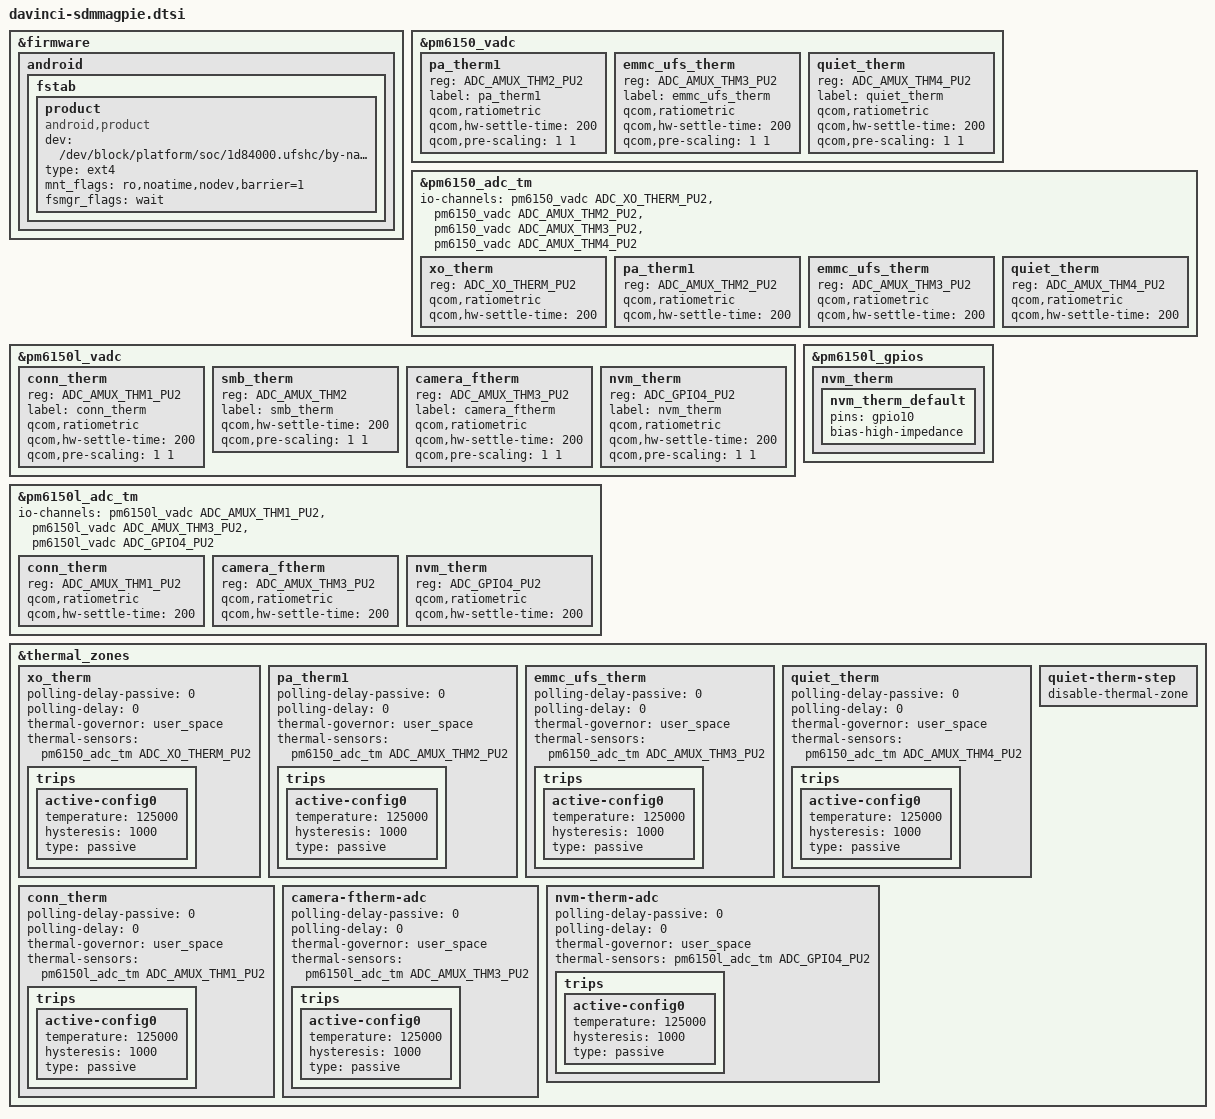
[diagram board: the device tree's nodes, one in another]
/*
 *
 * Copyright (C) 2020 The LineageOS Project
 *
 * this file is for attribution only of davinci
 * And public attribution of Xiaomi platforms (like F10 and so)
 */

#include "../common/xiaomi-sdmmagpie-common.dtsi"

#include "davinci-sdmmagpie-battery.dtsi"
#include "davinci-sdmmagpie-camera-sensor.dtsi"
#include "davinci-sdmmagpie-display.dtsi"
#include "davinci-sdmmagpie-fingerprint.dtsi"
#include "davinci-sdmmagpie-motor.dtsi"
#include "davinci-sdmmagpie-pinctrl.dtsi"
#include "davinci-sdmmagpie-touchscreen.dtsi"

&firmware {
    android {
        fstab {
            product {
              compatible = "android,product";
              dev = "/dev/block/platform/soc/1d84000.ufshc/by-name/cust";
              type = "ext4";
              mnt_flags = "ro,noatime,nodev,barrier=1";
              fsmgr_flags = "wait";
            };
        };
    };
};


&pm6150_vadc {
    pa_therm1 {
        reg = <ADC_AMUX_THM2_PU2>;
        label = "pa_therm1";
        qcom,ratiometric;
        qcom,hw-settle-time = <200>;
        qcom,pre-scaling = <1 1>;
    };

    emmc_ufs_therm {
        reg = <ADC_AMUX_THM3_PU2>;
        label = "emmc_ufs_therm";
        qcom,ratiometric;
        qcom,hw-settle-time = <200>;
        qcom,pre-scaling = <1 1>;
    };

    quiet_therm {
        reg = <ADC_AMUX_THM4_PU2>;
        label = "quiet_therm";
        qcom,ratiometric;
        qcom,hw-settle-time = <200>;
        qcom,pre-scaling = <1 1>;
    };
};

&pm6150_adc_tm {
    io-channels = <&pm6150_vadc ADC_XO_THERM_PU2>,
            <&pm6150_vadc ADC_AMUX_THM2_PU2>,
            <&pm6150_vadc ADC_AMUX_THM3_PU2>,
            <&pm6150_vadc ADC_AMUX_THM4_PU2>;

    /* Channel nodes */
    xo_therm {
        reg = <ADC_XO_THERM_PU2>;
        qcom,ratiometric;
        qcom,hw-settle-time = <200>;
    };

    pa_therm1 {
        reg = <ADC_AMUX_THM2_PU2>;
        qcom,ratiometric;
        qcom,hw-settle-time = <200>;
    };

    emmc_ufs_therm {
        reg = <ADC_AMUX_THM3_PU2>;
        qcom,ratiometric;
        qcom,hw-settle-time = <200>;
    };

    quiet_therm {
        reg = <ADC_AMUX_THM4_PU2>;
        qcom,ratiometric;
        qcom,hw-settle-time = <200>;
    };
};

&pm6150l_vadc {

    conn_therm {
        reg = <ADC_AMUX_THM1_PU2>;
        label = "conn_therm";
        qcom,ratiometric;
        qcom,hw-settle-time = <200>;
        qcom,pre-scaling = <1 1>;
    };

    smb_therm {
        reg = <ADC_AMUX_THM2>;
        label = "smb_therm";
        qcom,hw-settle-time = <200>;
        qcom,pre-scaling = <1 1>;
    };

    camera_ftherm {
        reg = <ADC_AMUX_THM3_PU2>;
        label = "camera_ftherm";
        qcom,ratiometric;
        qcom,hw-settle-time = <200>;
        qcom,pre-scaling = <1 1>;
    };

    nvm_therm {
        reg = <ADC_GPIO4_PU2>;
        label = "nvm_therm";
        qcom,ratiometric;
        qcom,hw-settle-time = <200>;
        qcom,pre-scaling = <1 1>;
    };
};

&pm6150l_gpios {
    nvm_therm {
        nvm_therm_default: nvm_therm_default {
            pins = "gpio10";
            bias-high-impedance;
        };
    };
};

&pm6150l_adc_tm {
    io-channels = <&pm6150l_vadc ADC_AMUX_THM1_PU2>,
            <&pm6150l_vadc ADC_AMUX_THM3_PU2>,
            <&pm6150l_vadc ADC_GPIO4_PU2>;

    /* Channel nodes */
    conn_therm {
        reg = <ADC_AMUX_THM1_PU2>;
        qcom,ratiometric;
        qcom,hw-settle-time = <200>;
    };

    camera_ftherm {
        reg = <ADC_AMUX_THM3_PU2>;
        qcom,ratiometric;
        qcom,hw-settle-time = <200>;
    };

    nvm_therm {
        reg = <ADC_GPIO4_PU2>;
        qcom,ratiometric;
        qcom,hw-settle-time = <200>;
    };
};

&thermal_zones {

    xo_therm {
        polling-delay-passive = <0>;
        polling-delay = <0>;
        thermal-governor = "user_space";
        thermal-sensors = <&pm6150_adc_tm ADC_XO_THERM_PU2>;
        trips {
            active-config0 {
                temperature = <125000>;
                hysteresis = <1000>;
                type = "passive";
            };
        };
    };

    pa_therm1 {
        polling-delay-passive = <0>;
        polling-delay = <0>;
        thermal-governor = "user_space";
        thermal-sensors = <&pm6150_adc_tm ADC_AMUX_THM2_PU2>;
        trips {
            active-config0 {
                temperature = <125000>;
                hysteresis = <1000>;
                type = "passive";
            };
        };
    };

    emmc_ufs_therm {
        polling-delay-passive = <0>;
        polling-delay = <0>;
        thermal-governor = "user_space";
        thermal-sensors = <&pm6150_adc_tm ADC_AMUX_THM3_PU2>;
        trips {
            active-config0 {
                temperature = <125000>;
                hysteresis = <1000>;
                type = "passive";
            };
        };
    };

    quiet_therm {
        polling-delay-passive = <0>;
        polling-delay = <0>;
        thermal-governor = "user_space";
        thermal-sensors = <&pm6150_adc_tm ADC_AMUX_THM4_PU2>;
        trips {
            active-config0 {
                temperature = <125000>;
                hysteresis = <1000>;
                type = "passive";
            };
        };
    };

    conn_therm {
        polling-delay-passive = <0>;
        polling-delay = <0>;
        thermal-governor = "user_space";
        thermal-sensors = <&pm6150l_adc_tm ADC_AMUX_THM1_PU2>;
        trips {
            active-config0 {
                temperature = <125000>;
                hysteresis = <1000>;
                type = "passive";
            };
        };
    };

    camera-ftherm-adc {
        polling-delay-passive = <0>;
        polling-delay = <0>;
        thermal-governor = "user_space";
        thermal-sensors = <&pm6150l_adc_tm ADC_AMUX_THM3_PU2>;
        trips {
            active-config0 {
                temperature = <125000>;
                hysteresis = <1000>;
                type = "passive";
            };
        };
    };

    nvm-therm-adc {
        polling-delay-passive = <0>;
        polling-delay = <0>;
        thermal-governor = "user_space";
        thermal-sensors = <&pm6150l_adc_tm ADC_GPIO4_PU2>;
        trips {
            active-config0 {
                temperature = <125000>;
                hysteresis = <1000>;
                type = "passive";
            };
        };
    };

    quiet-therm-step {
        disable-thermal-zone;
    };
};
